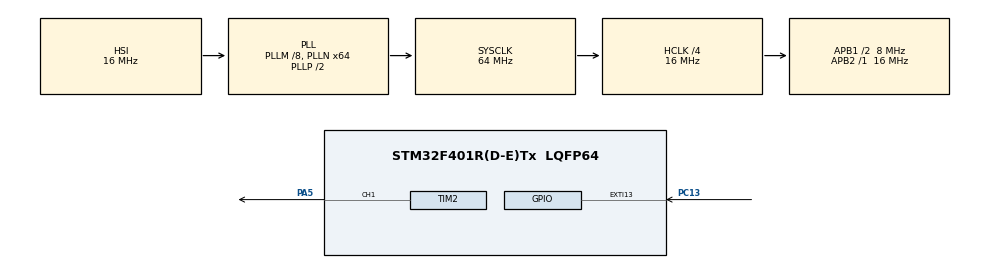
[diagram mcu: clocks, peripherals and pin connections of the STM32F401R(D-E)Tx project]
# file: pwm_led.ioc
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Mcu.Family=STM32F4
Mcu.Name=STM32F401R(D-E)Tx
Mcu.Package=LQFP64
NVIC.EXTI15_10_IRQn=true\:0\:0\:false\:true\:true\:1\:true\:true\:true
NVIC.PriorityGroup=NVIC_PRIORITYGROUP_0
NVIC.TIM1_UP_TIM10_IRQn=true\:0\:0\:false\:true\:true\:2\:true\:true\:true
PA13.GPIO_Label=TMS
PA13.Mode=Serial_Wire
PA13.Signal=SYS_JTMS-SWDIO
PA14.GPIO_Label=TCK
PA14.Mode=Serial_Wire
PA14.Signal=SYS_JTCK-SWCLK
PA5.Signal=S_TIM2_CH1_ETR
PB3.GPIO_Label=SWO
PB3.Signal=SYS_JTDO-SWO
PC13-ANTI_TAMP.GPIO_ModeDefaultEXTI=GPIO_MODE_IT_RISING
PC13-ANTI_TAMP.GPIO_PuPd=GPIO_NOPULL
PC13-ANTI_TAMP.Signal=GPXTI13
PC14-OSC32_IN.Mode=LSE-External-Oscillator
PC14-OSC32_IN.Signal=RCC_OSC32_IN
PC15-OSC32_OUT.Mode=LSE-External-Oscillator
PC15-OSC32_OUT.Signal=RCC_OSC32_OUT
PH0\ -\ OSC_IN.Mode=HSE-External-Clock-Source
PH0\ -\ OSC_IN.Signal=RCC_OSC_IN
PH1\ -\ OSC_OUT.Mode=HSE-External-Clock-Source
PH1\ -\ OSC_OUT.Signal=RCC_OSC_OUT
ProjectManager.HeapSize=0x200
ProjectManager.StackSize=0x400
ProjectManager.TargetToolchain=STM32CubeIDE
RCC.48MHZClocksFreq_Value=18285714.285714287
RCC.AHBCLKDivider=RCC_SYSCLK_DIV4
RCC.AHBFreq_Value=16000000
RCC.APB1CLKDivider=RCC_HCLK_DIV2
RCC.APB1Freq_Value=8000000
RCC.APB1TimFreq_Value=16000000
RCC.APB2Freq_Value=16000000
RCC.APB2TimFreq_Value=16000000
RCC.CortexFreq_Value=16000000
RCC.HCLKFreq_Value=16000000
RCC.HSE_VALUE=8000000
RCC.HSI_VALUE=16000000
RCC.PLLM=8
RCC.PLLN=64
RCC.PLLQ=7
RCC.SYSCLKFreq_VALUE=64000000
RCC.SYSCLKSource=RCC_SYSCLKSOURCE_PLLCLK
RCC.VCOOutputFreq_Value=128000000
SH.S_TIM2_CH1_ETR.0=TIM2_CH1,PWM Generation1 CH1
TIM1.Period=200-1
TIM1.Prescaler=16000-1
TIM1.TIM_MasterOutputTrigger=TIM_TRGO_OC1
TIM2.Channel-PWM\ Generation1\ CH1=TIM_CHANNEL_1
TIM2.Period=499
TIM2.Prescaler=671
VP_TIM1_VS_ClockSourceINT.Mode=Internal
VP_TIM2_VS_ClockSourceINT.Mode=Internal
board=NUCLEO-F401RE

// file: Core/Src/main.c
/* USER CODE BEGIN Header */
/**
  ******************************************************************************
  * @file           : main.c
  * @brief          : Main program body
  ******************************************************************************
  * @attention
  *
  * Copyright (c) 2022 STMicroelectronics.
  * All rights reserved.
  *
  * This software is licensed under terms that can be found in the LICENSE file
  * in the root directory of this software component.
  * If no LICENSE file comes with this software, it is provided AS-IS.
  *
  ******************************************************************************
  */
/* USER CODE END Header */
#include "main.h"

TIM_HandleTypeDef htim1;
TIM_HandleTypeDef htim2;

/* USER CODE BEGIN PV */
volatile uint32_t pwm_value = PWM_MIN;  // Initial PWM value

volatile _Bool check_update = False;
/* USER CODE END PV */

void SystemClock_Config(void);
static void MX_GPIO_Init(void);
static void MX_TIM2_Init(void);
static void MX_TIM1_Init(void);
static void MX_NVIC_Init(void);
/* USER CODE BEGIN PFP */
void SystemClock_Config(void);
static void MX_GPIO_Init(void);
static void MX_TIM2_Init(void);
static void MX_NVIC_Init(void);
/* USER CODE END PFP */

/* USER CODE BEGIN 0 */
void HAL_TIM_PeriodElapsedCallback(TIM_HandleTypeDef *htim)
{
    if (htim->Instance == TIM1) {
        if (check_update == False) {
            check_update = True;
        } else if (check_update == True) {
            check_update = False;
        }
    }
}
/* USER CODE END 0 */

int main(void)
{

    /* MCU Configuration--------------------------------------------------------*/

    /* Reset of all peripherals, Initializes the Flash interface and the Systick. */
    HAL_Init();

    /* Configure the system clock */
    SystemClock_Config();

    /* Initialize all configured peripherals */
    MX_GPIO_Init();
    MX_TIM2_Init();
    MX_TIM1_Init();

    /* Initialize interrupts */
    MX_NVIC_Init();
    /* USER CODE BEGIN 2 */
    TIM_SET_UG(TIM1);             // Set update generation flag

    TIM_RESET_UIF(TIM1);          // Reset update interrupt flag

    HAL_TIM_Base_Start_IT(&htim1);

    HAL_TIM_PWM_Start(&htim2, TIM_CHANNEL_1);

    /* USER CODE END 2 */

    /* Infinite loop */
    /* USER CODE BEGIN WHILE */
    while (1) {
        if (check_update == False) {
            tim_set_peak(TIM1, DELAY_VALUE_LED_ON);

            pwm_set(TIM2, pwm_value);
        } else if (check_update == True) {
            tim_set_peak(TIM1, DELAY_VALUE_LED_OFF);

            pwm_set(TIM2, PWM_VALUE_LED_OFF);
        }

        /* USER CODE END WHILE */

    }
}

void SystemClock_Config(void)
{
    RCC_OscInitTypeDef RCC_OscInitStruct = {0};
    RCC_ClkInitTypeDef RCC_ClkInitStruct = {0};

    /** Configure the main internal regulator output voltage
    */
    __HAL_RCC_PWR_CLK_ENABLE();
    __HAL_PWR_VOLTAGESCALING_CONFIG(PWR_REGULATOR_VOLTAGE_SCALE2);

    /** Initializes the RCC Oscillators according to the specified parameters
    * in the RCC_OscInitTypeDef structure.
    */
    RCC_OscInitStruct.OscillatorType = RCC_OSCILLATORTYPE_HSI;
    RCC_OscInitStruct.HSIState = RCC_HSI_ON;
    RCC_OscInitStruct.HSICalibrationValue = RCC_HSICALIBRATION_DEFAULT;
    RCC_OscInitStruct.PLL.PLLState = RCC_PLL_ON;
    RCC_OscInitStruct.PLL.PLLSource = RCC_PLLSOURCE_HSI;
    RCC_OscInitStruct.PLL.PLLM = 8;
    RCC_OscInitStruct.PLL.PLLN = 64;
    RCC_OscInitStruct.PLL.PLLP = RCC_PLLP_DIV2;
    RCC_OscInitStruct.PLL.PLLQ = 7;
    if (HAL_RCC_OscConfig(&RCC_OscInitStruct) != HAL_OK) {
        Error_Handler();
    }

    /** Initializes the CPU, AHB and APB buses clocks
    */
    RCC_ClkInitStruct.ClockType = RCC_CLOCKTYPE_HCLK | RCC_CLOCKTYPE_SYSCLK
                                  | RCC_CLOCKTYPE_PCLK1 | RCC_CLOCKTYPE_PCLK2;
    RCC_ClkInitStruct.SYSCLKSource = RCC_SYSCLKSOURCE_PLLCLK;
    RCC_ClkInitStruct.AHBCLKDivider = RCC_SYSCLK_DIV4;
    RCC_ClkInitStruct.APB1CLKDivider = RCC_HCLK_DIV2;
    RCC_ClkInitStruct.APB2CLKDivider = RCC_HCLK_DIV1;

    if (HAL_RCC_ClockConfig(&RCC_ClkInitStruct, FLASH_LATENCY_0) != HAL_OK) {
        Error_Handler();
    }
}

/**
  * @brief NVIC Configuration.
  * @retval None
  */
static void MX_NVIC_Init(void)
{
    /* EXTI15_10_IRQn interrupt configuration */
    HAL_NVIC_SetPriority(EXTI15_10_IRQn, 0, 0);
    HAL_NVIC_EnableIRQ(EXTI15_10_IRQn);
    /* TIM1_UP_TIM10_IRQn interrupt configuration */
    HAL_NVIC_SetPriority(TIM1_UP_TIM10_IRQn, 0, 0);
    HAL_NVIC_EnableIRQ(TIM1_UP_TIM10_IRQn);
}

static void MX_TIM1_Init(void)
{

    TIM_ClockConfigTypeDef sClockSourceConfig = {0};
    TIM_MasterConfigTypeDef sMasterConfig = {0};

    htim1.Instance = TIM1;
    htim1.Init.Prescaler = 16000 - 1;
    htim1.Init.CounterMode = TIM_COUNTERMODE_UP;
    htim1.Init.Period = 200 - 1;
    htim1.Init.ClockDivision = TIM_CLOCKDIVISION_DIV1;
    htim1.Init.RepetitionCounter = 0;
    htim1.Init.AutoReloadPreload = TIM_AUTORELOAD_PRELOAD_DISABLE;
    if (HAL_TIM_Base_Init(&htim1) != HAL_OK) {
        Error_Handler();
    }
    sClockSourceConfig.ClockSource = TIM_CLOCKSOURCE_INTERNAL;
    if (HAL_TIM_ConfigClockSource(&htim1, &sClockSourceConfig) != HAL_OK) {
        Error_Handler();
    }
    sMasterConfig.MasterOutputTrigger = TIM_TRGO_OC1;
    sMasterConfig.MasterSlaveMode = TIM_MASTERSLAVEMODE_DISABLE;
    if (HAL_TIMEx_MasterConfigSynchronization(&htim1, &sMasterConfig) != HAL_OK) {
        Error_Handler();
    }

}

static void MX_TIM2_Init(void)
{

    TIM_ClockConfigTypeDef sClockSourceConfig = {0};
    TIM_MasterConfigTypeDef sMasterConfig = {0};
    TIM_OC_InitTypeDef sConfigOC = {0};

    htim2.Instance = TIM2;
    htim2.Init.Prescaler = 671;
    htim2.Init.CounterMode = TIM_COUNTERMODE_UP;
    htim2.Init.Period = 499;
    htim2.Init.ClockDivision = TIM_CLOCKDIVISION_DIV1;
    htim2.Init.AutoReloadPreload = TIM_AUTORELOAD_PRELOAD_DISABLE;
    if (HAL_TIM_Base_Init(&htim2) != HAL_OK) {
        Error_Handler();
    }
    sClockSourceConfig.ClockSource = TIM_CLOCKSOURCE_INTERNAL;
    if (HAL_TIM_ConfigClockSource(&htim2, &sClockSourceConfig) != HAL_OK) {
        Error_Handler();
    }
    if (HAL_TIM_PWM_Init(&htim2) != HAL_OK) {
        Error_Handler();
    }
    sMasterConfig.MasterOutputTrigger = TIM_TRGO_RESET;
    sMasterConfig.MasterSlaveMode = TIM_MASTERSLAVEMODE_DISABLE;
    if (HAL_TIMEx_MasterConfigSynchronization(&htim2, &sMasterConfig) != HAL_OK) {
        Error_Handler();
    }
    sConfigOC.OCMode = TIM_OCMODE_PWM1;
    sConfigOC.Pulse = 0;
    sConfigOC.OCPolarity = TIM_OCPOLARITY_HIGH;
    sConfigOC.OCFastMode = TIM_OCFAST_DISABLE;
    if (HAL_TIM_PWM_ConfigChannel(&htim2, &sConfigOC, TIM_CHANNEL_1) != HAL_OK) {
        Error_Handler();
    }
    HAL_TIM_MspPostInit(&htim2);

}

static void MX_GPIO_Init(void)
{
    GPIO_InitTypeDef GPIO_InitStruct = {0};

    /* GPIO Ports Clock Enable */
    __HAL_RCC_GPIOC_CLK_ENABLE();
    __HAL_RCC_GPIOH_CLK_ENABLE();
    __HAL_RCC_GPIOA_CLK_ENABLE();
    __HAL_RCC_GPIOB_CLK_ENABLE();

    /*Configure GPIO pin : PC13 */
    GPIO_InitStruct.Pin = GPIO_PIN_13;
    GPIO_InitStruct.Mode = GPIO_MODE_IT_RISING;
    GPIO_InitStruct.Pull = GPIO_NOPULL;
    HAL_GPIO_Init(GPIOC, &GPIO_InitStruct);

}

/* USER CODE BEGIN 4 */
void HAL_GPIO_EXTI_Callback(uint16_t GPIO_Pin)
{
    if (GPIO_Pin == GPIO_PIN_13) {
        pwm_value += PWM_STEP;            // Adding the PWM step to the current valu

        if (pwm_value > PWM_MAX) {
            pwm_value = PWM_MIN;         // Setting the minimum PWM value in case the maximum value is exceeded
        }

    }
}

/* USER CODE END 4 */

void Error_Handler(void)
{
    __disable_irq();
    while (1) {
    }
}
